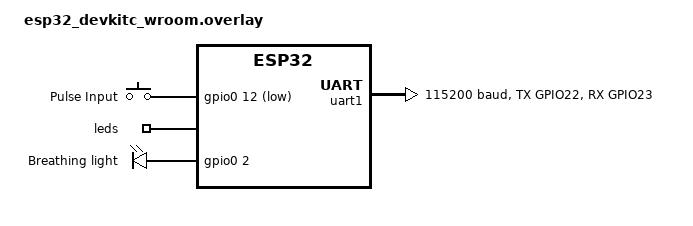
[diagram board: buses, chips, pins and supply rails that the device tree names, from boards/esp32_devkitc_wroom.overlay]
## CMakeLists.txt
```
# SPDX-License-Identifier: Apache-2.0

cmake_minimum_required(VERSION 3.20.0)
find_package(Zephyr REQUIRED HINTS $ENV{ZEPHYR_BASE})
project(pulse_counter)

# set include dir
include_directories(src/include)

target_sources(app PRIVATE src/main.c 
                           src/pulse_counter.c
                           src/breathing_light.c
                           src/lorawan_uart_smartmodular.c)
```

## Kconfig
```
mainmenu "Pulse counter project"

config BREATHING_LIGHT_TASK_PRIO
    int "Breathing light task priority"
    default 7
    
config BREATHING_LIGHT_TASK_STACK_SIZE
    int "Breathing light task stack size"
    default 1024

config PULSE_COUNTER_TASK_PRIO
    int "Breathing light task priority"
    default 8
        
config PULSE_COUNTER_TASK_STACK_SIZE
    int "Breathing light task stack size"
    default 1024

config PULSE_COUNTER_VRBOSE_DEBUG_ENABLE
    bool "Enable/disable pulse counter verbose debug"
    default y 
        

source "Kconfig.zephyr"   
```

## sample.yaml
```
sample:
  name: Pulse counter project
tests:
  sample.basic.button:
    tags:
      - button
      - gpio
      - pulse
      - uart
      - led
    filter: dt_enabled_alias_with_parent_compat("pulseinput", "gpio-keys")
            dt_enabled_alias_with_parent_compat("led0", "gpio-leds")
    integration_platforms:
      - esp32c3_devkitm
      - esp32_devkitc_wroom
      - rpi_pico
    depends_on: gpio
                uart
                led
    harness: pulse counter
```

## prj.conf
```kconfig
CONFIG_GPIO=y
CONFIG_HEAP_MEM_POOL_SIZE=256
CONFIG_SERIAL=y
CONFIG_LOG=y
```

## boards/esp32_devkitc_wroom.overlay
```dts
/ {
    aliases {
        pulseinput = &button1;
        led0 = &led0;
    };
};

/ {
    buttons {
        compatible = "gpio-keys";
        button1: button_1 {
            gpios = <&gpio0 12 (GPIO_PULL_UP | GPIO_ACTIVE_LOW)>;
			label = "Pulse Input";
			zephyr,code = <INPUT_KEY_1>;
        };

     leds {
        compatible = "gpio-leds";
        led0: led {
            gpios = <&gpio0 2 GPIO_ACTIVE_HIGH>;
            label = "Breathing light";
        };
      };   
    };
};

&pinctrl {
uart1_default: uart1_default {
		group1 {
			pinmux = <UART1_TX_GPIO22>;
		};
		group2 {
			pinmux = <UART1_RX_GPIO23>;
			bias-pull-up;
		};
	};
};

&uart1 {
	current-speed = <115200>;
	pinctrl-0 = <&uart1_default>;
	pinctrl-names = "default";
    status = "okay";
};
```

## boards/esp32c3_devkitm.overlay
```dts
/ {
    aliases {
        pulseinput = &button1;
        led0 = &led0;
    };
};

/ {
    buttons {
        compatible = "gpio-keys";
        button1: button_1 {
            gpios = <&gpio0 3 (GPIO_PULL_UP | GPIO_ACTIVE_LOW)>;
			label = "Pulse Input";
			zephyr,code = <INPUT_KEY_1>;
        };

     leds {
        compatible = "gpio-leds";
        led0: led {
            gpios = <&gpio0 4 GPIO_ACTIVE_HIGH>;
            label = "Breathing light";
        };
      };   
    };
};

&pinctrl {
uart1_default: uart1_default {
		group1 {
			pinmux = <UART1_TX_GPIO6>;
		};
		group2 {
			pinmux = <UART1_RX_GPIO7>;
			bias-pull-up;
		};
	};
};

&uart1 {
	current-speed = <115200>;
	pinctrl-0 = <&uart1_default>;
	pinctrl-names = "default";
    status = "okay";
};
```

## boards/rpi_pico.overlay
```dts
#include <dt-bindings/input/input-event-codes.h>

/ {
    aliases {
        pulseinput = &button1;
        led0 = &led0;
    };
};

/ {
    buttons {
        compatible = "gpio-keys";
        status = "okay";
        
        button1: button_1 {
            gpios = <&gpio0 2 (GPIO_PULL_UP | GPIO_ACTIVE_LOW)>;
			label = "Pulse Input";
			zephyr,code = <INPUT_KEY_1>;
        };  
    };

    leds {
        status = "okay";
    };   
};

&pinctrl {
        uart1_default: uart1_default {
		group1 {
			pinmux = <UART1_TX_P4>;
		};
		group2 {
			pinmux = <UART1_RX_P5>;
			input-enable;
		};
	};
};

&uart1 {
        current-speed = <115200>;
	    status = "okay";
	    pinctrl-0 = <&uart1_default>;
	    pinctrl-names = "default";
};
```

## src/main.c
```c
/*
 * Pulse counter project
 * Author: Pedro Bertoleti
 */

#include <zephyr/kernel.h>
#include <zephyr/device.h>
#include <zephyr/sys/util.h>
#include <zephyr/logging/log.h>
#include "pulse_counter.h"
#include "breathing_light.h"
#include "lorawan_uart_smartmodular.h"

LOG_MODULE_REGISTER(pulse_counter_lorawan);

int main(void)
{
	int ret_init_lorawan = 0;
	int ret_init_breathing_light = 0;
	int ret_init_pulse_counter = 0;

	LOG_INF("Starting pulse counter project..."); 

    ret_init_breathing_light = init_breathing_light();
    ret_init_lorawan = init_lorawan_smartmodular_uart();	
    ret_init_pulse_counter = init_pulse_counter();	

	if ( (ret_init_breathing_light == 1) && (ret_init_lorawan == 1) && 
	     (ret_init_pulse_counter == 1) )
	{
        LOG_INF("All pulse counter project modules have been successfully started");
	}
	else
	{
		LOG_ERR("Some modules experienced errors in their init routines.");
	}

	return 0;
}
```

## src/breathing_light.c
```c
#include <zephyr/kernel.h>
#include <zephyr/device.h>
#include <zephyr/drivers/gpio.h>
#include <zephyr/sys/printk.h>
#include <zephyr/sys/__assert.h>
#include <zephyr/logging/log.h>
#include "breathing_light.h"

LOG_MODULE_DECLARE(pulse_counter_lorawan);

/* Specify which node is used for LED in device tree*/
#define LED0_NODE DT_ALIAS(led0)

/* Define time for toggling breathing light LED */
#define BREATHING_LIGHT_TIME_MS              1000

/* Define thread stack size */
K_THREAD_STACK_DEFINE(breathing_light_thread_stack, CONFIG_BREATHING_LIGHT_TASK_STACK_SIZE);

/* Load beathing light LED device tree data */
static const struct gpio_dt_spec led = GPIO_DT_SPEC_GET(LED0_NODE, gpios);

/* Pulse counter thread data */
struct k_thread breathing_light_thread_data;

/* Prototype of breathing light task */
void breathing_light_task(void *p1, void *p2, void *p3);

/* Function: init breathing light, by setting up LED output
 * Params: none
 * Return: 0: error
 *         1: ok
 */
int init_breathing_light(void)
{
    int ret;
	int init_breathing_light_status = 0;

    LOG_INF("Starting breathing light module...");

	if (!gpio_is_ready_dt(&led)) 
    {
		init_breathing_light_status = 0;
		goto END_BREATHING_LIGHT_INIT;
	}

	ret = gpio_pin_configure_dt(&led, GPIO_OUTPUT_ACTIVE);
	if (ret < 0) 
    {
		init_breathing_light_status = 0;
		goto END_BREATHING_LIGHT_INIT;
	}

    /* Create pulse counter thread */
    k_thread_create(&breathing_light_thread_data, breathing_light_thread_stack,
			      K_THREAD_STACK_SIZEOF(breathing_light_thread_stack),
			      breathing_light_task, NULL, NULL, NULL,
			      CONFIG_BREATHING_LIGHT_TASK_PRIO, 0, K_NO_WAIT);

    LOG_INF("Breathing light module has been started");				  

    init_breathing_light_status = 1;
	
END_BREATHING_LIGHT_INIT:
    return init_breathing_light_status;
}

/* Function: init breathing light, by setting up LED output
 * Params: none
 * Return: none
 */
void breathing_light_task(void *p1, void *p2, void *p3)
{
    while (1) 
    {
		gpio_pin_toggle_dt(&led);
		k_msleep(BREATHING_LIGHT_TIME_MS);
	}
}
```

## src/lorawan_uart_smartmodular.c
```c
#include <zephyr/kernel.h>
#include <zephyr/device.h>
#include <zephyr/drivers/uart.h>
#include <stdio.h>
#include <string.h>
#include <zephyr/logging/log.h>
#include "lorawan_uart_smartmodular.h"

LOG_MODULE_DECLARE(pulse_counter_lorawan);

/* Define time to receive response from smart modular lorawan module */
#define TIME_TO_RECEIVE_RESPONSE   1000 //ms

/* Define LoRaWAN Port (for LoRaWAN communication) */
#define LORAWAN_PORT               12

/* Load device tree defs for lorawan uart */
const struct device *uart_lorawan = DEVICE_DT_GET(DT_NODELABEL(uart1));

/* LoRaWAN ABP credentials */
static const char DEVADDR[] = "00:00:00:00";
static const char APPSKEY[] = "00:00:00:00:00:00:00:00:00:00:00:00:00:00:00:00";
static const char NWKSKEY[] = "00:00:00:00:00:00:00:00:00:00:00:00:00:00:00:00";
static const char APPEUI[] = "00:00:00:00:00:00:00:00";

/* Struct for lorawan uart configuration */
struct uart_config uart_cfg = {
	.baudrate = 9600,
	.parity = PARITY_LORAWAN_UART,
	.stop_bits = STOP_BITS_LORAWAN_UART,
	.flow_ctrl = FLOW_CTRL_LORAWAN_UART,
	.data_bits = DATA_BITS_LORAWAN_UART,
};

/* Local functions prototypes */
void wake_up_lorawan_smartmodular_uart(void);
void reset_lorawan_smartmodular_uart(void);
void join_mode_abp_smartmodular_uart(void);
void class_A_smartmodular_uart(void);
void device_address_smartmodular_uart(void);
void appskey_smartmodular_uart(void);
void nwskey_smartmodular_uart(void);
void appeui_smartmodular_uart(void);
void send_custom_at_command_lorawan_smartmodular_uart(char *at_command);
void rcv_response_lorawan_smartmodular_uart(void);

/* Function: init smart modular lorawan module uart communication
 * Params: none
 * Return: 0: error
 *         1: ok
 */
int init_lorawan_smartmodular_uart(void)
{
    int rc;
	int init_lorawan_smartmodular_uart_status = 0;

    LOG_INF("Starting LoRaWAN UART Smart Modular module...");

    rc = uart_configure(uart_lorawan, &uart_cfg);
    
    if (rc)
    {
        LOG_INF("Failed to configure lorawan uart");
		init_lorawan_smartmodular_uart_status = 0;
		goto END_INIT_LORAWAN_SMART_MODULAR;
	}
   
    /* Wake up lorawan module */
	wake_up_lorawan_smartmodular_uart();

	/* Reset lorawan module */
	reset_lorawan_smartmodular_uart();

	/* Configure join mode as ABP */
	join_mode_abp_smartmodular_uart();

	/* Configure LoRaWAN class as A */
	class_A_smartmodular_uart();

	/* Configure Device Address */
	device_address_smartmodular_uart();

	/* Configure Application Session Key */
    appskey_smartmodular_uart();

	/* Configure Network Session Key */
	nwskey_smartmodular_uart();

	/* Configure Application EUI */
	appeui_smartmodular_uart();

    LOG_INF("LoRaWAN UART Smart Modular module has been started");
    init_lorawan_smartmodular_uart_status = 1;

END_INIT_LORAWAN_SMART_MODULAR:	
	return init_lorawan_smartmodular_uart_status;
}

/* Function: send AT command to wake up lorawan module
 * Params: none
 * Return: none
 */
void wake_up_lorawan_smartmodular_uart(void)
{
    char at_cmd[100] = {0};

	memset(at_cmd, 0x00, sizeof(at_cmd));
	snprintf(at_cmd, sizeof(at_cmd), "%s%s", AT_CMD_WAKE, AT_CMD_TERMINATOR);
	send_custom_at_command_lorawan_smartmodular_uart(at_cmd);
	k_msleep(TIME_TO_RECEIVE_RESPONSE);
    rcv_response_lorawan_smartmodular_uart();
}

/* Function: send AT command to reset lorawan module
 * Params: none
 * Return: none
 */
void reset_lorawan_smartmodular_uart(void)
{
    char at_cmd[100] = {0};

	memset(at_cmd, 0x00, sizeof(at_cmd));
	snprintf(at_cmd, sizeof(at_cmd), "%s%s", AT_CMD_RESET, AT_CMD_TERMINATOR);
	send_custom_at_command_lorawan_smartmodular_uart(at_cmd);
	k_msleep(TIME_TO_RECEIVE_RESPONSE);
    rcv_response_lorawan_smartmodular_uart();
}

/* Function: send AT command to configure join mode as ABP
 * Params: none
 * Return: none
 */
void join_mode_abp_smartmodular_uart(void)
{
    char at_cmd[100] = {0};

	memset(at_cmd, 0x00, sizeof(at_cmd));
	snprintf(at_cmd, sizeof(at_cmd), "%s%s", AT_CMD_JOIN_MODE_ABP, AT_CMD_TERMINATOR);
	send_custom_at_command_lorawan_smartmodular_uart(at_cmd);
	k_msleep(TIME_TO_RECEIVE_RESPONSE);
    rcv_response_lorawan_smartmodular_uart();
}

/* Function: send AT command to configure lorawan class as A
 * Params: none
 * Return: none
 */
void class_A_smartmodular_uart(void)
{
	char at_cmd[100] = {0};

	memset(at_cmd, 0x00, sizeof(at_cmd));
	snprintf(at_cmd, sizeof(at_cmd), "%s%s", AT_CMD_CLASS, AT_CMD_TERMINATOR);
	send_custom_at_command_lorawan_smartmodular_uart(at_cmd);
	k_msleep(TIME_TO_RECEIVE_RESPONSE);
    rcv_response_lorawan_smartmodular_uart();
}

/* Function: send AT command to configure lorawan class as A
 * Params: none
 * Return: none
 */
void device_address_smartmodular_uart(void)
{
	char at_cmd[100] = {0};

	memset(at_cmd, 0x00, sizeof(at_cmd));
	snprintf(at_cmd, sizeof(at_cmd), "%s=%s%s", AT_CMD_DEVADDR, DEVADDR, AT_CMD_TERMINATOR);
	send_custom_at_command_lorawan_smartmodular_uart(at_cmd);
	k_msleep(TIME_TO_RECEIVE_RESPONSE);
    rcv_response_lorawan_smartmodular_uart();
}

/* Function: send AT command to configure lorawan application session key
 * Params: none
 * Return: none
 */
void appskey_smartmodular_uart(void)
{
    char at_cmd[100] = {0};

	memset(at_cmd, 0x00, sizeof(at_cmd));
	snprintf(at_cmd, sizeof(at_cmd), "%s=%s%s", AT_CMD_APPSKEY, APPSKEY, AT_CMD_TERMINATOR);
	send_custom_at_command_lorawan_smartmodular_uart(at_cmd);
	k_msleep(TIME_TO_RECEIVE_RESPONSE);
    rcv_response_lorawan_smartmodular_uart();
}

/* Function: send AT command to configure lorawan network session key
 * Params: none
 * Return: none
 */
void nwskey_smartmodular_uart(void)
{
    char at_cmd[100] = {0};

	memset(at_cmd, 0x00, sizeof(at_cmd));
	snprintf(at_cmd, sizeof(at_cmd), "%s=%s%s", AT_CMD_NWSKEY, NWKSKEY, AT_CMD_TERMINATOR);
	send_custom_at_command_lorawan_smartmodular_uart(at_cmd);
	k_msleep(TIME_TO_RECEIVE_RESPONSE);
    rcv_response_lorawan_smartmodular_uart();
}

/* Function: send AT command to configure lorawan application eui
 * Params: none
 * Return: none
 */
void appeui_smartmodular_uart(void)
{
    char at_cmd[100] = {0};

	memset(at_cmd, 0x00, sizeof(at_cmd));
	snprintf(at_cmd, sizeof(at_cmd), "%s=%s%s", AT_CMD_APPEUI, APPEUI, AT_CMD_TERMINATOR);
	send_custom_at_command_lorawan_smartmodular_uart(at_cmd);
	k_msleep(TIME_TO_RECEIVE_RESPONSE);
    rcv_response_lorawan_smartmodular_uart();
}

/* Function: send pulse counter as LoRaWAN message
 * Params: pulse counter
 * Return: none
 */
void send_pulse_counter(int total_pulses)
{
    char at_cmd[100] = {0};
	
	memset(at_cmd, 0x00, sizeof(at_cmd));
	snprintf(at_cmd, sizeof(at_cmd), "%s=%d:%08X%s", AT_CMD_SEND_BYTE, LORAWAN_PORT, total_pulses, AT_CMD_TERMINATOR);
	send_custom_at_command_lorawan_smartmodular_uart(at_cmd);
	k_msleep(TIME_TO_RECEIVE_RESPONSE);
    rcv_response_lorawan_smartmodular_uart();
}

/* Function: send custom AT command to smart modular lorawan module
 * Params: pointer to char array containing string
 * Return: none
 */
void send_custom_at_command_lorawan_smartmodular_uart(char *at_command)
{
	int msg_len = strlen(at_command);
    int i = 0;

	for (i=0; i<msg_len; i++) 
    {
		uart_poll_out(uart_lorawan, at_command[i]);
	}
}

/* Function: receive response from smart modular lorawan module
 * Params: 
 * Return: none
 */
void rcv_response_lorawan_smartmodular_uart(void)
{
    char c;
		
    LOG_INF("Bytes received from LoRaWAN module:");

	while (!uart_poll_in(uart_lorawan, &c)) 
	{
        LOG_INF("%c", c);
	}
}
```

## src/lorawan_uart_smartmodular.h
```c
/* Header file: smart modular (lorawan module) */
#include <zephyr/drivers/uart.h>

#ifndef HEADER_LORAWAN_UART
#define HEADER_LORAWAN_UART

/* UART parametrization */
#define BAUDRATE_LORAWAN_UART    9600
#define PARITY_LORAWAN_UART      UART_CFG_PARITY_NONE
#define STOP_BITS_LORAWAN_UART   UART_CFG_STOP_BITS_1
#define FLOW_CTRL_LORAWAN_UART   UART_CFG_FLOW_CTRL_NONE
#define DATA_BITS_LORAWAN_UART   UART_CFG_DATA_BITS_8

/* AT Commands */
#define AT_CMD_TERMINATOR        "\n"
#define AT_CMD_WAKE              "AT"
#define AT_CMD_RESET             "ATZ"
#define AT_CMD_JOIN_MODE_ABP     "AT+NJM=0"
#define AT_CMD_CLASS             "AT+CLASS=A"
#define AT_CMD_DEVADDR           "AT+DADDR"
#define AT_CMD_APPSKEY           "AT+APPSKEY"
#define AT_CMD_NWSKEY            "AT+NWKSKEY"
#define AT_CMD_APPEUI            "AT+APPEUI"
#define AT_CMD_SEND_BYTE         "AT+SENDB"

#endif

/* Prototypes */
int init_lorawan_smartmodular_uart(void);
void send_pulse_counter(int total_pulses);
```

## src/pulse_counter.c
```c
#include <zephyr/kernel.h>
#include <zephyr/device.h>
#include <zephyr/drivers/gpio.h>
#include <zephyr/sys/util.h>
#include <string.h>
#include <zephyr/logging/log.h>
#include "pulse_counter.h"
#include "lorawan_uart_smartmodular.h"

LOG_MODULE_DECLARE(pulse_counter_lorawan);

/*
 * Get pulse input configuration from the devicetree pulseinput alias.
 */
#define PULSEINPUT_NODE	DT_ALIAS(pulseinput)

/* Define time for toggling breathing light LED */
#define PULSE_COUNTER_TIME_MS              1000

/* Define time for main loop iteraction */
#define SLEEP_TIME_MS	60000

/* Define time used for debounce pulse input */
#define PULSE_DEBOUNCE_TIME    300  //ms

/* Pulse counter variable */
static int pulse_counter = 0;

/* Pulse debounce timer */
static struct k_timer pulse_debounce_timer;

/* Pulse counter thread data */
struct k_thread pulse_counter_thread_data;

#if !DT_NODE_HAS_STATUS(PULSEINPUT_NODE, okay)
#error "Unsupported board: pulseinput devicetree alias is not defined"
#endif
static const struct gpio_dt_spec pulseinput = GPIO_DT_SPEC_GET_OR(PULSEINPUT_NODE, gpios,
							      {0});
static struct gpio_callback pulseinput_cb_data;

/* Prototype of breathing light task */
void pulse_counter_task(void *p1, void *p2, void *p3);

/* Pulse debounce timer callback */
static void pulse_debounce_timer_callback(struct k_timer *timer);

/* Define thread stack */
K_THREAD_STACK_DEFINE(pulse_counter_thread_stack, CONFIG_PULSE_COUNTER_TASK_STACK_SIZE);

/* Function: pulse detection callback
 * Params: callback params
 * Return: none
 */
void pulse_detected(const struct device *dev, struct gpio_callback *cb, uint32_t pins)
{
	#if CONFIG_PULSE_COUNTER_VRBOSE_DEBUG_ENABLE
        LOG_INF("[PULSE_COUNTER] Pulse has been detected");
    #endif

	k_timer_start(&pulse_debounce_timer, K_MSEC(PULSE_DEBOUNCE_TIME), K_NO_WAIT);
}

/* Function: timer callback, used for debouncing pulses
 * Params: callback params
 * Return: none
 */
static void pulse_debounce_timer_callback(struct k_timer *timer)
{
	#if CONFIG_PULSE_COUNTER_VRBOSE_DEBUG_ENABLE
        LOG_INF("[PULSE_COUNTER] Pulse count has been updated!");
    #endif

	pulse_counter++;
}


/* Function: init pulse counter,  by setting up pulse counter input
 *           and pulse counter initial value
 * Params: none
 * Return: 0: error
 *         1: ok
 */
int init_pulse_counter(void)
{
    int ret;

    if (!gpio_is_ready_dt(&pulseinput)) 
	{
		#if CONFIG_PULSE_COUNTER_VRBOSE_DEBUG_ENABLE
            LOG_INF("[PULSE_COUNTER] Error: pulse input device %s is not ready", pulseinput.port->name);
        #endif

		return 0;
	}

	ret = gpio_pin_configure_dt(&pulseinput, GPIO_INPUT);
	if (ret != 0) 
	{
        #if CONFIG_PULSE_COUNTER_VRBOSE_DEBUG_ENABLE
		    LOG_INF("[PULSE_COUNTER] Error %d: failed to configure %s pin %d", ret, pulseinput.port->name, pulseinput.pin);
        #endif

		return 0;
	}

    /* Configure pulse interrupt edge as rising edge */
	ret = gpio_pin_interrupt_configure_dt(&pulseinput,
					      GPIO_INT_EDGE_TO_ACTIVE);
	if (ret != 0) 
	{
		#if CONFIG_PULSE_COUNTER_VRBOSE_DEBUG_ENABLE 
            LOG_INF("[PULSE_COUNTER] Error %d: failed to configure interrupt on %s pin %d", ret, pulseinput.port->name, pulseinput.pin);
        #endif

		return 0;
	}

	gpio_init_callback(&pulseinput_cb_data, pulse_detected, BIT(pulseinput.pin));
	gpio_add_callback(pulseinput.port, &pulseinput_cb_data);
	
    #if CONFIG_PULSE_COUNTER_VRBOSE_DEBUG_ENABLE
        LOG_INF("[PULSE_COUNTER] Set up pulse input at %s pin %d\n", pulseinput.port->name, pulseinput.pin);
    #endif

    /* Init pulse debounce timer */
    k_timer_init(&pulse_debounce_timer, pulse_debounce_timer_callback, NULL);

	/* Init pulse counter */
	pulse_counter = 0;

    #if CONFIG_PULSE_COUNTER_VRBOSE_DEBUG_ENABLE
	    LOG_INF("[PULSE_COUNTER] All set! Ready to read pulses");
    #endif

    /* Create pulse counter thread */
    k_thread_create(&pulse_counter_thread_data, pulse_counter_thread_stack,
			      K_THREAD_STACK_SIZEOF(pulse_counter_thread_stack),
			      pulse_counter_task, NULL, NULL, NULL,
			      CONFIG_PULSE_COUNTER_TASK_PRIO, 0, K_NO_WAIT);

    return 1;
}

/* Function: obtain pulse counter value
 * Params: none
 * Return: pulse counter value
 */
int get_pulse_counter(void)
{
    return pulse_counter;
}

/* Function: pulse counter task for monitoring pulses counter
 * Params: none
 * Return: none
 */
void pulse_counter_task(void *p1, void *p2, void *p3)
{
    while (1) 
	{
        /* Main loop */
		#if CONFIG_PULSE_COUNTER_VRBOSE_DEBUG_ENABLE
		    LOG_INF("[PULSE_COUNTER] Pulse counter value: %d", get_pulse_counter());
		#endif

        /* Send pulse counter as a LoRaWAN message */
        send_pulse_counter(pulse_counter);

        /* Thread cycle delay */
		k_msleep(SLEEP_TIME_MS);
	}
}
```

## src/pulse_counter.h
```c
/* Header file: pulse counter */

#ifndef HEADER_PULSE_COUNTER
#define HEADER_PULSE_COUNTER

#endif

/* Prototypes */
int init_pulse_counter(void);
int get_pulse_counter(void);
```
